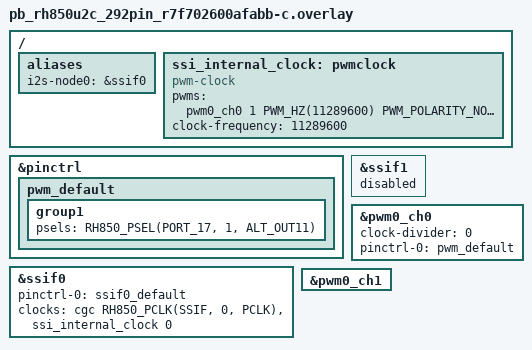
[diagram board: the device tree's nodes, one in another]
/*
 * Copyright (c) 2026 Renesas Electronics Corporation
 *
 * SPDX-License-Identifier: Apache-2.0
 */

#include <dt-bindings/pinctrl/renesas/pinctrl-rh850u2c.h>
#include <zephyr/dt-bindings/pwm/pwm.h>

/ {
	aliases {
		i2s-node0 = &ssif0;
	};
};

/ {
	ssi_internal_clock: pwmclock {
		compatible = "pwm-clock";
		status = "okay";

		#clock-cells = <1>;

		pwms = <&pwm0_ch0
			1
			PWM_HZ(11289600)
			PWM_POLARITY_NORMAL>;

		clock-frequency = <11289600>;
	};
};

&pinctrl {
	pwm_default: pwm_default {
		group1 {
			/* TAUD0O1 */
			psels = <RH850_PSEL(PORT_17, 1, ALT_OUT11)>;
		};
	};
};

&ssif0 {
	pinctrl-0 = <&ssif0_default>;
	pinctrl-names = "default";

	clocks = <&cgc RH850_PCLK(SSIF, 0, PCLK)>,
		 <&ssi_internal_clock 0>;

	clock-names = "pclk", "audio-clock";

	status = "okay";
};

&ssif1 {
	status = "disabled";
};

&pwm0_ch0 {
	clock-divider = <0>;
	pinctrl-0 = <&pwm_default>;
	pinctrl-names = "default";
	status = "okay";
};

&pwm0_ch1 {
	status = "okay";
};
